# apollo510 register map
Vendor: Ambiq Micro; Series: Apollo; File version: 1.0
CPU: CM55 r1p1, little endian, MPU, FPU, double-precision FPU, DSP, I-cache, D-cache, VTOR, ITCM, DTCM, 4 interrupt priority bits, 0 interrupts, 8 SAU regions
Registers are 32-bit, read-write, reset 0x0 unless marked. A register's access mark holds for its fields unless they carry their own. Offsets are from the block's base; [hi:lo] are bit positions.

## UART0 — Serial UART
Base 0x40039000
Same registers: UART1 0x4003A000, UART2 0x4003B000, UART3 0x4003C000
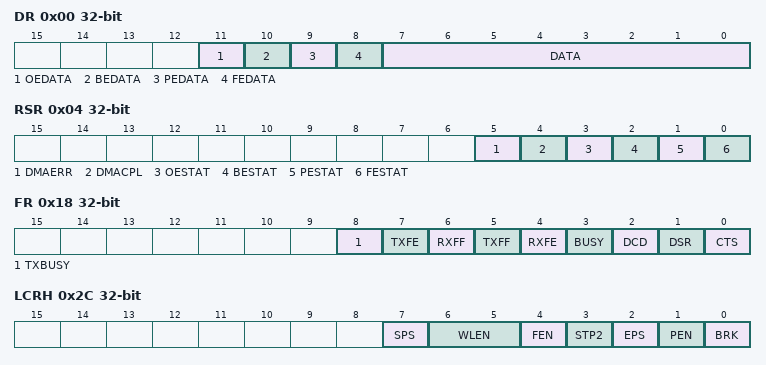
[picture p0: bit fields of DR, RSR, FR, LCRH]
0x00 DR — UART Data
  [11] OEDATA — Overrun error. This bit is set to 1 if data is received and the receive FIFO is already full. This is cleared to 0 once there is an empty space in the FIFO and a new character can be written to it.
    0=NOERR (No error on UART OEDATA, overrun error indicator.); 1=ERR (Error on UART OEDATA, overrun error indicator.)
  [10] BEDATA — Break error. This bit is set to 1 if a break condition was detected, indicating that the received data input was held LOW for longer than a full-word transmission time (defined as start, data, parity and stop bits). In FIFO mode, this error is associated with the character at the top of the FIFO. When a break occurs, only one 0 character is loaded into the FIFO. The next character is only enabled after the receive data input goes to a 1 (marking state), and the next valid start bit is received.
    0=NOERR (No error on UART BEDATA, break error indicator.); 1=ERR (Error on UART BEDATA, break error indicator.)
  [9] PEDATA — Parity error. When set to 1, it indicates that the parity of the received data character does not match the parity that the EPS and SPS bits in the Line Control Register, UARTLCRH select. In FIFO mode, this error is associated with the character at the top of the FIFO.
    0=NOERR (No error on UART PEDATA, parity error indicator.); 1=ERR (Error on UART PEDATA, parity error indicator.)
  [8] FEDATA — Framing error. When set to 1, it indicates that the received character did not have a valid stop bit (a valid stop bit is 1). In FIFO mode, this error is associated with the character at the top of the FIFO.
    0=NOERR (No error on UART FEDATA, framing error indicator.); 1=ERR (Error on UART FEDATA, framing error indicator.)
  [7:0] DATA — Receive (read) data character. Transmit (write) data character.
0x04 RSR — UART Status
  [5] DMAERR — This is the DMA transfer error indicator.
    0=NOERR (DMA transfer no error indicator.); 1=ERROR (DMA transfer error indicator.)
  [4] DMACPL — This is the DMA transfer complete indicator.
    0=NOCPL (DMA transfer not complete indicator.); 1=CPL (DMA transfer complete indicator.)
  [3] OESTAT — Overrun error. This bit is set to 1 if data is received and the FIFO is already full. This bit is cleared to 0 by a write to UARTECR. The FIFO contents remain valid because no more data is written when the FIFO is full, only the contents of the shift register are overwritten. The CPU must now read the data, to empty the FIFO.
    0=NOERR (No error on UART OESTAT, overrun error indicator.); 1=ERR (Error on UART OESTAT, overrun error indicator.)
  [2] BESTAT — Break error. This bit is set to 1 if a break condition was detected, indicating that the received data input was held LOW for longer than a full-word transmission time (defined as start, data, parity, and stop bits). This bit is cleared to 0 after a write to UARTECR. In FIFO mode, this error is associated with the character at the top of the FIFO. When a break occurs, only one 0 character is loaded into the FIFO. The next character is only enabled after the receive data input goes to a 1 (marking state) and the next valid start bit is received.
    0=NOERR (No error on UART BESTAT, break error indicator.); 1=ERR (Error on UART BESTAT, break error indicator.)
  [1] PESTAT — Parity error. When set to 1, it indicates that the parity of the received data character does not match the parity that the EPS and SPS bits in the Line Control Register, UARTLCRH select. This bit is cleared to 0 by a write to UARTECR. In FIFO mode, this error is associated with the character at the top of the FIFO.
    0=NOERR (No error on UART PESTAT, parity error indicator.); 1=ERR (Error on UART PESTAT, parity error indicator.)
  [0] FESTAT — Framing error. When set to 1, it indicates that the received character did not have a valid stop bit (a valid stop bit is 1). This bit is cleared to 0 by a write to UARTECR. In FIFO mode, this error is associated with the character at the top of the FIFO.
    0=NOERR (No error on UART FESTAT, framing error indicator.); 1=ERR (Error on UART FESTAT, framing error indicator.)
0x18 FR — Flags
  [8] TXBUSY — This bit holds the transmit BUSY indicator.
  [7] TXFE — Transmit FIFO empty. The meaning of this bit depends on the state of the FEN bit in the Line Control Register, UARTLCRH. If the FIFO is disabled, this bit is set when the transmit holding register is empty. If the FIFO is enabled, the TXFE bit is set when the transmit FIFO is empty. This bit does not indicate if there is data in the transmit shift register.
    1=XMTFIFO_EMPTY (Transmit fifo is empty.); 0=XMTFIFO_NOTEMPTY (Transmit fifo is not empty.)
  [6] RXFF — Receive FIFO full. The meaning of this bit depends on the state of the FEN bit in the UARTLCRH Register. If the FIFO is disabled, this bit is set when the receive holding register is full. If the FIFO is enabled, the RXFF bit is set when the receive FIFO is full.
    1=RCVFIFO_FULL (Receive fifo is full.); 0=RCVFIFO_NOTFULL (Receive fifo is not full.)
  [5] TXFF — Transmit FIFO full. The meaning of this bit depends on the state of the FEN bit in the UARTLCRH Register. If the FIFO is disabled, this bit is set when the transmit holding register is full. If the FIFO is enabled, the TXFF bit is set when the transmit FIFO is full.
    1=XMTFIFO_FULL (Transmit fifo is full.); 0=XMTFIFO_NOTFULL (Transmit fifo is not full.)
  [4] RXFE — Receive FIFO empty. The meaning of this bit depends on the state of the FEN bit in the UARTLCRH Register. If the FIFO is disabled, this bit is set when the receive holding register is empty. If the FIFO is enabled, the RXFE bit is set when the receive FIFO is empty.
    1=RCVFIFO_EMPTY (Receive fifo is empty.); 0=RCVFIFO_NOTEMPTY (Receive fifo is not empty.)
  [3] BUSY — UART busy. If this bit is set to 1, the UART is busy transmitting data. This bit remains set until the complete byte, including all the stop bits, has been sent from the shift register. This bit is set as soon as the transmit FIFO becomes non-empty, regardless of whether the UART is enabled or not.
    1=BUSY (UART busy indicator.); 0=NOTBUSY (UART not busy.)
  [2] DCD — Data carrier detect. This bit is the complement of the UART data carrier detect, nUARTDCD, modem status input. That is, the bit is 1 when nUARTDCD is LOW.
    1=DETECTED (Data carrier detect detected.); 0=DEFAULT (Data carrier detect not detected/default.)
  [1] DSR — Data set ready. This bit is the complement of the UART data set ready, nUARTDSR, modem status input. That is, the bit is 1 when nUARTDSR is LOW.
    1=READY (Data set ready.); 0=NOTREADY (Data set not ready/default.)
  [0] CTS — Clear to send. This bit is the complement of the UART clear to send, nUARTCTS, modem status input. That is, the bit is 1 when nUARTCTS is LOW.
    1=CLEARTOSEND (Clear to send is indicated.); 0=DEFAULT (Clear to send default value.)
0x20 ILPR — IrDA Counter
  [7:0] ILPDVSR — 8-bit low-power divisor value. These bits are cleared to 0 at reset. Programming a zero value results in no IrLPBaud16 pulses being generated.
0x24 IBRD — Integer Baud Rate Divisor
  [15:0] DIVINT — This field holds the integer baud rate divisor. It is set in conjunction with the DIVFRAC field in the FBRD register and the clock rate as set in the CLKSEL field of the CR register. The field should be set to the integer part of the ratio: Clock Rate / (16 x intended baud rate).
0x28 FBRD — Fractional Baud Rate Divisor
  [5:0] DIVFRAC — This field holds the fractional baud rate divisor. It is set in conjunction with the DIVINT field in the IBRD register and the clock rate as set in the CLKSEL field of the CR register. The field should be set to the rounded value of 64 x the fractional part of the ratio: Clock Rate / (16 x intended baud rate).
0x2C LCRH — Line Control High
  [7] SPS — This bit holds the stick parity select. If the EPS bit is 0 then the parity bit is transmitted and checked as a 1. If the EPS bit is 1 then the parity bit is transmitted and checked as a 0. This bit has no effect when the PEN bit disables parity checking and generation.
  [6:5] WLEN — These bits hold the write length. These bits indicate the number of data bits transmitted or received in a frame as follows: b11 = 8 bits, b10 = 7 bits, b01 = 6 bits, b00 = 5 bits.
  [4] FEN — This bit holds the FIFO enable. 0 = FIFOs are disabled (character mode) that is, the FIFOs become 1-byte-deep holding registers. 1 = transmit and receive FIFO buffers are enabled (FIFO mode).
  [3] STP2 — This bit holds the two stop bits select. If this bit is set to 1, two stop bits are transmitted at the end of the frame. The receive logic does not check for two stop bits being received.
  [2] EPS — This bit holds the even parity select. Controls the type of parity the UART uses during transmission and reception: 0 = odd parity. The UART generates or checks for an odd number of 1s in the data and parity bits. 1 = even parity. The UART generates or checks for an even number of 1s in the data and parity bits. This bit has no effect when the PEN bit disables parity checking and generation.
  [1] PEN — This bit holds the parity enable. 0 = parity is disabled and no parity bit added to the data frame. 1 = parity checking and generation is enabled.
  [0] BRK — This bit holds the break set. If this bit is set to 1, a low-level is continually output on the UARTTXD output, after completing transmission of the current character. For the proper execution of the break command, the software must set this bit for at least two complete frames. For normal use, this bit must be cleared to 0.
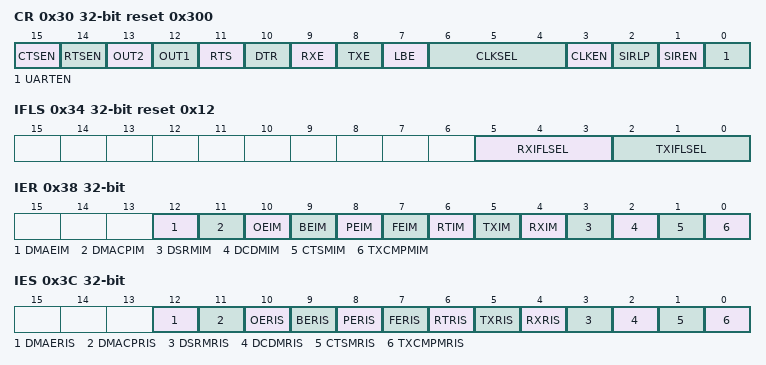
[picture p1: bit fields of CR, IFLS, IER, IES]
0x30 CR reset 0x300 — Control
  [15] CTSEN — This bit enables CTS hardware flow control. If this bit is set to 1, CTS hardware flow control is enabled. Data is only transmitted when the nUARTCTS signal is asserted.
  [14] RTSEN — This bit enables RTS hardware flow control. If this bit is set to 1, RTS hardware flow control is enabled. Data is only requested when there is space in the receive FIFO for it to be received.
  [13] OUT2 — This bit is the complement of the UART Out2 (nUARTOut2) modem status output. That is, when the bit is programmed to a 1, the output is 0. For DTE this can be used as Ring Indicator (RI).
  [12] OUT1 — This bit is the complement of the UART Out1 (nUARTOut1) modem status output. That is, when the bit is programmed to a 1 the output is 0. For DTE this can be used as Data Carrier Detect (DCD).
  [11] RTS — This bit enables request to send. This bit is the complement of the UART request to send, nUARTRTS, modem status output. That is, when the bit is programmed to a 1 then nUARTRTS is LOW.
  [10] DTR — This bit enables data transmit ready. This bit is the complement of the UART data transmit ready, nUARTDTR, modem status output. That is, when the bit is programmed to a 1 then nUARTDTR is LOW.
  [9] RXE — This bit is the receive enable. If this bit is set to 1, the receive section of the UART is enabled. Data reception occurs for either UART signals or SIR signals depending on the setting of the SIREN bit. When the UART is disabled in the middle of reception, it completes the current character before stopping.
  [8] TXE — This bit is the transmit enable. If this bit is set to 1, the transmit section of the UART is enabled. Data transmission occurs for either UART signals, or SIR signals depending on the setting of the SIREN bit. When the UART is disabled in the middle of transmission, it completes the current character before stopping.
  [7] LBE — This bit is the loopback enable. If this bit is set to 1 and the SIREN bit is set to 1 and the SIRTEST bit in the Test Control Register, UARTTCR is set to 1, then the nSIROUT path is inverted, and fed through to the SIRIN path. The SIRTEST bit in the test register must be set to 1 to override the normal half-duplex SIR operation. This must be the requirement for accessing the test registers during normal operation, and SIRTEST must be cleared to 0 when loopback testing is finished. This feature reduces the amount of external coupling required during system test. If this bit is set to 1, and the SIRTEST bit is set to 0, the UARTTXD path is fed through to the UARTRXD path. In either SIR mode or UART mode, when this bit is set, the modem outputs are also fed through to the modem inputs. This bit is cleared to 0 on reset, to disable loopback.
  [6:4] CLKSEL — This bitfield is the UART clock select.
    0=OFF (No UART clock. This is the low power default); 1=HFRC_24MHZ (24 MHz sourced from the HFRC); 2=HFRC_12MHZ (12 MHz sourced from the HFRC); 3=HFRC_6MHZ (6 MHz sourced from the HFRC); 4=HFRC_3MHZ (3 MHz sourced from the HFRC); 5=HFRC_48MHZ (48 MHz sourced from the HFRC); 6=PLL_CLK (Sourced from the PLL)
  [3] CLKEN — This bit is the UART clock enable.
  [2] SIRLP — This bit is the SIR low power select. This bit selects the IrDA encoding mode. If this bit is cleared to 0, low-level bits are transmitted as an active high pulse with a width of 3/16th of the bit period. If this bit is set to 1, low-level bits are transmitted with a pulse width which is 3 times the period of the IrLPBaud16 input signal, regardless of the selected bit rate. Setting this bit uses less power, but might reduce transmission distances.
  [1] SIREN — This bit is the SIR ENDEC enable. If this bit is set to 1, the IrDA SIR ENDEC is enabled. This bit has no effect if the UART is not enabled by bit 0 being set to 1. When the IrDA SIR ENDEC is enabled, data is transmitted and received on nSIROUT and SIRIN. UARTTXD remains in the marking state (set to 1). Signal transitions on UARTRXD or modem status inputs have no effect. When the IrDA SIR ENDEC is disabled, nSIROUT remains cleared to 0 (no light pulse generated), and signal transitions on SIRIN have no effect.
  [0] UARTEN — This bit is the UART enable. 0 = UART is disabled. If the UART is disabled in the middle of transmission or reception, it completes the current character before stopping. 1 = the UART is enabled. Data transmission and reception occurs for either UART signals or SIR signals depending on the setting of the SIREN bit.
0x34 IFLS reset 0x12 — FIFO Interrupt Level Select
  [5:3] RXIFLSEL — These bits hold the receive FIFO interrupt level.
  [2:0] TXIFLSEL — These bits hold the transmit FIFO interrupt level.
0x38 IER — Interrupt Enable
  [12] DMAEIM — This bit holds the DMA error interrupt enable.
  [11] DMACPIM — This bit holds the DMA complete interrupt enable.
  [10] OEIM — This bit holds the overflow interrupt enable.
  [9] BEIM — This bit holds the break error interrupt enable.
  [8] PEIM — This bit holds the parity error interrupt enable.
  [7] FEIM — This bit holds the framing error interrupt enable.
  [6] RTIM — This bit holds the receive timeout interrupt enable.
  [5] TXIM — This bit holds the transmit interrupt enable.
  [4] RXIM — This bit holds the receive interrupt enable.
  [3] DSRMIM — This bit holds the modem DSR interrupt enable.
  [2] DCDMIM — This bit holds the modem DCD interrupt enable.
  [1] CTSMIM — This bit holds the modem CTS interrupt enable.
  [0] TXCMPMIM — This bit holds the modem TXCMP interrupt enable.
0x3C IES — Interrupt Status
  [12] DMAERIS — This bit holds the DMA error interrupt status.
  [11] DMACPRIS — This bit holds the DMA complete interrupt status.
  [10] OERIS — This bit holds the overrun interrupt status. Returns the raw interrupt state of the UARTOEINTR interrupt.
  [9] BERIS — This bit holds the break error interrupt status. Returns the raw interrupt state of the UARTBEINTR interrupt.
  [8] PERIS — This bit holds the parity error interrupt status. Returns the raw interrupt state of the UARTPEINTR interrupt.
  [7] FERIS — This bit holds the framing error interrupt status. Returns the raw interrupt state of the UARTFEINTR interrupt.
  [6] RTRIS — This bit holds the receive timeout interrupt status. Returns the raw interrupt state of the UARTRTINTR interrupt.
  [5] TXRIS — This bit holds the transmit interrupt status. Returns the raw interrupt state of the UARTTXINTR interrupt.
  [4] RXRIS — This bit holds the receive interrupt status. Returns the raw interrupt state of the UARTRXINTR interrupt.
  [3] DSRMRIS — This bit holds the nUARTDSR modem interrupt status. Returns the raw interrupt state of the UARTDSRINTR interrupt.
  [2] DCDMRIS — This bit holds the nUARTDCD modem interrupt status. Returns the raw interrupt state of the UARTDCDINTR interrupt.
  [1] CTSMRIS — This bit holds the nUARTCTS modem interrupt status. Returns the raw interrupt state of the UARTCTSINTR interrupt.
  [0] TXCMPMRIS — This bit holds the modem TXCMP interrupt status.
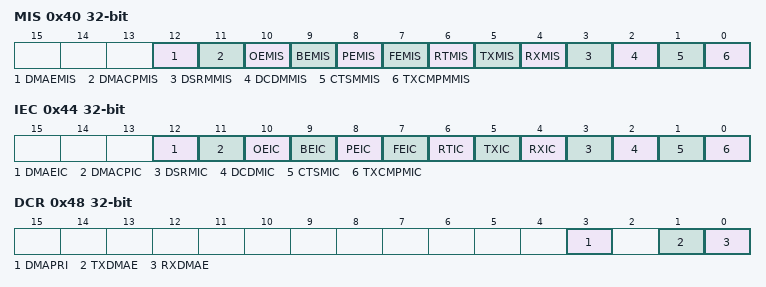
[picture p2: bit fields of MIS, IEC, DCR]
0x40 MIS — Masked Interrupt Status
  [12] DMAEMIS — This bit holds the DMA error interrupt status masked.
  [11] DMACPMIS — This bit holds the DMA complete interrupt status masked.
  [10] OEMIS — This bit holds the overrun interrupt status masked. Returns the masked interrupt state of the UARTOEINTR interrupt.
  [9] BEMIS — This bit holds the break error interrupt status masked. Returns the masked interrupt state of the UARTBEINTR interrupt.
  [8] PEMIS — This bit holds the parity error interrupt status masked. Returns the masked interrupt state of the UARTPEINTR interrupt.
  [7] FEMIS — This bit holds the framing error interrupt status masked. Returns the masked interrupt state of the UARTFEINTR interrupt.
  [6] RTMIS — This bit holds the receive timeout interrupt status masked. Returns the masked interrupt state of the UARTRTINTR interrupt.
  [5] TXMIS — This bit holds the transmit interrupt status masked. Returns the masked interrupt state of the UARTTXINTR interrupt.
  [4] RXMIS — This bit holds the receive interrupt status masked. Returns the masked interrupt state of the UARTRXINTR interrupt.
  [3] DSRMMIS — This bit holds the nUARTDSR modem masked interrupt status. Returns the masked interrupt state of the UARTDSRINTR interrupt.
  [2] DCDMMIS — This bit holds the nUARTDCD modem masked interrupt status. Returns the masked interrupt state of the UARTDCDINTR interrupt.
  [1] CTSMMIS — This bit holds the nUARTCTS modem masked interrupt status. Returns the masked interrupt state of the UARTCTSINTR interrupt.
  [0] TXCMPMMIS — This bit holds the modem TXCMP interrupt status masked.
0x44 IEC — Interrupt Clear
  [12] DMAEIC — This bit holds the DMA error interrupt clear.
  [11] DMACPIC — This bit holds the DMA complete interrupt clear.
  [10] OEIC — This bit holds the overrun interrupt clear. Clears the UARTOEINTR interrupt.
  [9] BEIC — This bit holds the break error interrupt clear. Clears the UARTBEINTR interrupt.
  [8] PEIC — This bit holds the parity error interrupt clear. Clears the UARTPEINTR interrupt.
  [7] FEIC — This bit holds the framing error interrupt clear. Clears the UARTFEINTR interrupt.
  [6] RTIC — This bit holds the receive timeout interrupt clear. Clears the UARTRTINTR interrupt.
  [5] TXIC — This bit holds the transmit interrupt clear. Clears the UARTTXINTR interrupt.
  [4] RXIC — This bit holds the receive interrupt clear. Clears the UARTRXINTR interrupt.
  [3] DSRMIC — This bit holds the nUARTDSR modem interrupt clear. Clears the UARTDSRINTR interrupt.
  [2] DCDMIC — This bit holds the nUARTDCD modem interrupt clear. Clears the UARTDCDINTR interrupt.
  [1] CTSMIC — This bit holds the nUARTCTS modem interrupt clear. Clears the UARTCTSINTR interrupt.
  [0] TXCMPMIC — This bit holds the modem TXCMP interrupt clear.
0x48 DCR — DMA Control
  [3] DMAPRI — This is DMA priority indicator.
    0=LOW (Low Priority (service as best effort).); 1=HIGH (High Priority (service immediately).)
  [1] TXDMAE — Enable DMA Function when Uart transmit. If this bit is set to 1, DMA for the transmit FIFO is enabled.
  [0] RXDMAE — Enable DMA Function when Uart Receive. If this bit is set to 1, DMA for the receive FIFO is enabled.
0x4C TARGADDR — DMA target address
  [31:0] TARGADDR — Bits [31:0] of the target byte address for source of DMA (either read or write). The address can be any byte alignment, and does not have to be word aligned. In cases of non-word aligned addresses, the DMA logic will take care for ensuring only the target bytes are read/written.
0x50 COUNT — Contains the number of bytes to be transferred for this DMA transaction.
  [11:0] TOTCOUNT — Total Transfer Count in bytes.
